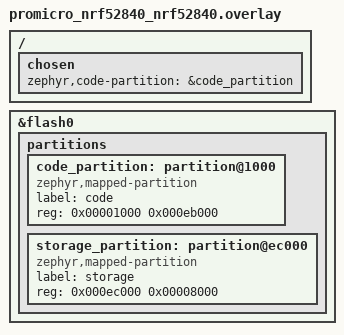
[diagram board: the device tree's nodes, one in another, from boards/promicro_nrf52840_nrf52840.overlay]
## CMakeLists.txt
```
#
# Copyright (c) 2025 Nordic Semiconductor ASA
#
# SPDX-License-Identifier: LicenseRef-Nordic-5-Clause
#

cmake_minimum_required(VERSION 3.20.0)

# The custom solomon,ssd1683 binding lives with the standalone app, one level up. Zephyr only
# looks for dts/bindings under the application directory, which is this one -- point it there
# too, or the e-paper node's width/height properties silently do not exist.
list(APPEND DTS_ROOT ${CMAKE_CURRENT_SOURCE_DIR}/..)

# The board's drivers, shared with the standalone firmware. Merged after prj.conf, so keep it free
# of anything an app would want to override -- see the file's header.
list(APPEND EXTRA_CONF_FILE ${CMAKE_CURRENT_SOURCE_DIR}/../conf/airink_hw.conf)

find_package(Zephyr HINTS $ENV{ZEPHYR_BASE})

project(matter-temperature-sensor)

# Enable GNU STD support.
include(${ZEPHYR_CONNECTEDHOMEIP_MODULE_DIR}/config/nrfconnect/app/enable-gnu-std.cmake)

# NORDIC SDK APP START

# Include all source files that are located in the Matter common directory.
include(${ZEPHYR_NRF_MODULE_DIR}/samples/matter/common/cmake/source_common.cmake)

# Include Data Model utils
include(${ZEPHYR_NRF_MODULE_DIR}/samples/matter/common/cmake/data_model.cmake)

include(${ZEPHYR_NRF_MODULE_DIR}/samples/matter/common/cmake/zap_helpers.cmake)
ncs_get_zap_parent_dir(ZAP_PARENT_DIR)

target_include_directories(app PRIVATE
  src
  ${ZAP_PARENT_DIR}
  # AirInk's own source tree, one level up.
  ${CMAKE_CURRENT_SOURCE_DIR}/../src
)

target_sources(app PRIVATE
  src/app_task.cpp
  src/main.cpp
)

# The AirInk device: the same sources the standalone firmware builds, minus its main() -- here
# app::run() is one thread among the CHIP event loop and OpenThread. Keep this list in step with
# the root CMakeLists.txt.
set(AIRINK_SRC ${CMAKE_CURRENT_SOURCE_DIR}/../src)
target_sources(app PRIVATE
  ${AIRINK_SRC}/app.cpp
  ${AIRINK_SRC}/menu.cpp
  ${AIRINK_SRC}/input/button.cpp
  ${AIRINK_SRC}/sensors/scd41.cpp
  ${AIRINK_SRC}/sensors/battery.cpp
  ${AIRINK_SRC}/ui/display_ui.cpp
  ${AIRINK_SRC}/ui/ui_platform.cpp
  # UI fonts (1bpp), generated via lv_font_conv: B612 for text, DSEG7 for values.
  ${AIRINK_SRC}/fonts/b612_48.c
  ${AIRINK_SRC}/fonts/b612_28.c
  ${AIRINK_SRC}/fonts/b612_16.c
  ${AIRINK_SRC}/fonts/b612_14.c
  ${AIRINK_SRC}/fonts/dseg7_48.c
  ${AIRINK_SRC}/fonts/dseg7_18.c
  # Vendored SSD16xx driver with a custom solomon,ssd1683 quirk (max 400x400, panel_gates=300)
  # for the GDEY042T81/SSD1683. Paired with CONFIG_SSD16XX=n.
  ${AIRINK_SRC}/drivers/ssd16xx.c
)

ncs_configure_data_model()
# NORDIC SDK APP END
```

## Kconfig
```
#
# Copyright (c) 2025 Nordic Semiconductor
#
# SPDX-License-Identifier: LicenseRef-Nordic-5-Clause
#
mainmenu "AirInk (Matter over Thread)"

choice OPENTHREAD_NORDIC_LIBRARY_CONFIGURATION
	default OPENTHREAD_NORDIC_LIBRARY_MTD
endchoice

choice OPENTHREAD_DEVICE_TYPE
	default OPENTHREAD_MTD
endchoice

config CHIP_ENABLE_ICD_SUPPORT
	default y

config CHIP_ICD_LIT_SUPPORT
	default y

config CHIP_ICD_SIT_SLOW_POLL_LIMIT
	default 5000

config CHIP_ICD_REPORT_ON_ACTIVE_MODE
	default y

# Reduce Thread TX output power to 0 dBm for SED device
config OPENTHREAD_DEFAULT_TX_POWER
	default 0

source "$(ZEPHYR_CONNECTEDHOMEIP_MODULE_DIR)/config/nrfconnect/chip-module/Kconfig.features"
source "$(ZEPHYR_CONNECTEDHOMEIP_MODULE_DIR)/config/nrfconnect/chip-module/Kconfig.defaults"
source "$(ZEPHYR_NRF_MODULE_DIR)/samples/matter/common/src/Kconfig"
source "Kconfig.zephyr"
```

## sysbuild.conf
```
#
# Copyright (c) 2025 Nordic Semiconductor
#
# SPDX-License-Identifier: LicenseRef-Nordic-5-Clause
#

SB_CONFIG_MATTER=y
SB_CONFIG_PARTITION_MANAGER=n

# No MCUboot: plain single image at 0x1000, flashed via the Adafruit UF2 bootloader
# (keeps AirInk's drag-drop field-update flow). Matter only imply's MCUboot, so this
# override is legal. Cost: no over-the-air OTA (would need external QSPI flash anyway).
SB_CONFIG_BOOTLOADER_NONE=y

# No factory data -- using the built-in example attestation provider (see prj.conf).
SB_CONFIG_MATTER_FACTORY_DATA_GENERATE=n

# No over-the-air OTA (no MCUboot). This is what injects CONFIG_CHIP_OTA_REQUESTOR into
# the app image; off here drops the DFU image manager (IMG_MANAGER/DFU_TARGET/
# STREAM_FLASH) that needs slot0/slot1 partitions we don't have. Field updates are UF2.
SB_CONFIG_MATTER_OTA=n
```

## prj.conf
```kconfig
#
# Copyright (c) 2025 Nordic Semiconductor ASA
#
# SPDX-License-Identifier: LicenseRef-Nordic-5-Clause
#

# Enable CHIP
CONFIG_CHIP=y
CONFIG_CHIP_PROJECT_CONFIG="src/chip_project_config.h"

# Configure ZAP file name
CONFIG_NCS_SAMPLE_MATTER_ZAP_FILE_PATH="${APPLICATION_CONFIG_DIR}/src/default_zap/airink.zap"

# Device identity -- what a controller shows in its UI (Basic Information cluster). Left
# unset, every one of these falls back to a sample/test default: product name
# "Matter Temperature Sensor", hardware version "prerelease", serial "11223344556677889900".
# The serial is the same on every board we flash; per-device serials would need factory
# data, which we deliberately dropped (see CHIP_FACTORY_DATA_NONE below).
CONFIG_CHIP_DEVICE_VENDOR_NAME="AirInk"
CONFIG_CHIP_DEVICE_PRODUCT_NAME="AirInk CO2 Monitor"
CONFIG_CHIP_DEVICE_HARDWARE_VERSION=1
CONFIG_CHIP_DEVICE_HARDWARE_VERSION_STRING="rev A"
CONFIG_CHIP_DEVICE_SERIAL_NUMBER="AIRINK-0001"
# The software version comes from the VERSION file (the Kconfig is hidden once APPVERSION
# is set), not from here.

# Based on https://github.com/project-chip/connectedhomeip/blob/482e6fd03196a6de45465a90003947ef4b86e0b1/docs/examples/discussion/PID_allocation_for_example_apps.md)
# 0x8000 (32768), to match the example provider's DAC (FFF1-8000). Was 32781 (0x800D).
CONFIG_CHIP_DEVICE_PRODUCT_ID=32768
CONFIG_STD_CPP17=y

# Enable Matter pairing automatically on application start.
CONFIG_CHIP_ENABLE_PAIRING_AUTOSTART=y

# Enable Matter extended announcement and increase duration to 1 hour.
CONFIG_CHIP_BLE_EXT_ADVERTISING=y
CONFIG_CHIP_BLE_ADVERTISING_DURATION=60

# The DK library drives the buttons and LEDs of a Nordic development kit. We have neither: one
# button, no status LEDs, and that button already belongs to Zephyr's gpio-keys + input-longpress
# drivers (src/input/button.cpp). Two owners on one pin is not a style question -- the DK library
# takes raw GPIO callbacks and *disables the pin interrupt* while it debounces, which is the same
# interrupt gpio-keys is using. Off. Nrf::Board and the LED widgets are wholly #ifdef'd on this,
# so they degrade to no-ops (and the sample's "LED index out of the range" boot error goes away).
CONFIG_DK_LIBRARY=n

# Bluetooth Low Energy configuration. This name is the only one actually on the air during
# BLE commissioning -- the Matter commissionable payload carries no device name (see
# CHIP_DEVICE_CONFIG_ENABLE_COMMISSIONABLE_DEVICE_NAME in chip_project_config.h), which is
# why a controller shows a generic "Matter Accessory" until it can read Basic Information.
CONFIG_BT_DEVICE_NAME="AirInk"
CONFIG_BT_DEVICE_NAME_MAX=18

# Suspend devices when the CPU goes into sleep
CONFIG_PM_DEVICE=y

# Other settings
CONFIG_THREAD_NAME=y
CONFIG_MPU_STACK_GUARD=y
CONFIG_RESET_ON_FATAL_ERROR=n
# Shell off for the bring-up (saves flash; RAM barely).
CONFIG_CHIP_LIB_SHELL=n

# Reduce application size
CONFIG_USE_SEGGER_RTT=n

# Built-in example attestation provider: it ships a complete, self-consistent set --
# DAC (FFF1/8000), PAI (FFF1), and a CD (kCdForAllExamples, covering PID 0x8000..) -- all
# hardcoded, no factory-data partition, no chip-cert host tool needed. The device's PID
# must be 0x8000 to match the example DAC (set below); the CD covers it. With HA's
# enable_test_net_dcl=true the test certs are trusted. Passcode stays custom (below).
CONFIG_CHIP_FACTORY_DATA_NONE=y
CONFIG_CHIP_DEVICE_SPAKE2_PASSCODE=528722
# The SPAKE2+ verifier is a STATIC Kconfig default -- it is NOT recomputed when the
# passcode changes. Its default belongs to passcode 20202021, so a custom passcode with
# the stock verifier makes the device advertise 528722 while proving knowledge of
# 20202021: the commissioner's Pake2 check fails and it drops BLE mid-PASE.
# Generated for passcode 528722 / this salt / 1000 iterations with
#   scripts/tools/spake2p/spake2p.py gen-verifier -p 528722 -s <salt> -i 1000
CONFIG_CHIP_DEVICE_SPAKE2_TEST_VERIFIER="LdCcPszn0rvDj59TPG1d2kQstzG8hR1Ty0PvpWUYgeUEPahM+o4wma7TlCWuMm8Z4blyJEp/VQdDBcCTW8c3JbFoMFvieDwXAbMtL/i3GSFf/d42EjivkDMMpDw2K9Fohg=="

# (OTA requestor is turned off at the sysbuild layer: SB_CONFIG_MATTER_OTA=n. It's
# injected via .config.sysbuild, which is merged AFTER prj.conf, so a prj.conf override
# here would be ignored -- the switch has to live in sysbuild.conf.)

# Matter has its own bootloader choice, separate from the sysbuild one, defaulting to
# CHIP_BOOTLOADER_MCUBOOT which hard-selects IMG_MANAGER (whose STREAM_FLASH dependency
# is now off). Pick NONE -- we have no MCUboot.
CONFIG_CHIP_BOOTLOADER_NONE=y

# NFC onboarding pulls in the NFC T2T nrfxlib, but the promicro board doesn't enable the
# nrfx NFCT driver (the DK does) -> undefined nrfx_nfct_* at link. We commission over BLE
# with the QR / manual code, so drop NFC onboarding.
CONFIG_CHIP_NFC_ONBOARDING_PAYLOAD=n

# The board's drivers -- SCD41, battery ADC, e-paper, LVGL, the button, the uart0 console, the
# UF2 output -- are not repeated here. They live in conf/airink_hw.conf, shared with the standalone
# firmware and pulled in by CMakeLists.txt. Below is only what this build decides differently.
#
# The one exception is the LVGL pool: it is a tuning knob, not a board fact, and this build cannot
# afford the standalone one's 48 KB.
# All views are built once and kept resident, and glyph draw buffers (b612_48 is ~2 KB) come out of
# the pool during a render. Running it dry is an MPU fault in lv_draw_label, not a graceful failure.
# Trimmed to the measured peak plus headroom -- ui::log_pool() reports "peak 17644 of 24576 B" at
# boot, with every view resident. If you raise the UI's appetite, read that line; do not guess.
CONFIG_LV_Z_MEM_POOL_SIZE=24576

# --- Stacks. RAM is what this build is short of; every kilobyte here is one the UI cannot have.
# main() no longer renders anything -- it only runs the CHIP task queue (AppTask::StartApp), and
# the 400x300 render with its 48 px glyph rasterisation moved to AirInk's own thread, which is
# sized for it in app_task.cpp. The sample's 6 KB was for a main that did the work.
CONFIG_MAIN_STACK_SIZE=3072
# The CHIP event loop. Our cluster writes take the stack lock from AirInk's thread rather than
# running here, so this carries Matter's own work only.
CONFIG_CHIP_TASK_STACK_SIZE=6144

# CHIP heap. The 10 KB default cannot build the NetworkCommissioning ScanNetworks
# response (cluster 0x0031 cmd 0x0000): the device returns NO_MEMORY ("Adding response
# failed: b"), the commissioner stalls, the fail-safe expires and the fabric is rolled
# back. Home Assistant issues ScanNetworks during commissioning (the phone framework does
# not, which is why that path used to get through). It looks like an obvious 8 KB to reclaim now
# that RAM is tight -- it is not.
CONFIG_CHIP_MALLOC_SYS_HEAP_SIZE=40960
```

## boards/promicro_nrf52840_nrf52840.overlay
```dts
/*
 * The Matter build's devicetree: AirInk's hardware (the shared .dtsi -- same SCD41, button,
 * e-paper, battery divider and uart0 console as the standalone firmware) plus the one thing
 * that differs, a partition map.
 *
 * No MCUboot, no external flash. Plain single image linked at 0x1000 -- exactly where the
 * Adafruit UF2 bootloader (top of flash) expects a SoftDevice-less app, the same layout the
 * standalone firmware ships with. Storage (Matter NVS) sits just below the reserved bootloader
 * region so the app never touches it.
 *
 * Flash map (1 MB):
 *   0x00000000  MBR (part of the Adafruit bootloader, already present)
 *   0x00001000  code       -> 0xEB000 = 940 KB
 *   0x000EC000  storage    -> 0x08000 = 32 KB    (Matter fabric NVS)
 *   0x000F4000  Adafruit bootloader + settings (48 KB) -- RESERVED, no partition
 */

#include "../../dts/airink_hw.dtsi"

/delete-node/ &boot_partition;
/delete-node/ &slot0_partition;
/delete-node/ &slot1_partition;
/delete-node/ &storage_partition;

/ {
	chosen {
		zephyr,code-partition = &code_partition;
	};
};

&flash0 {
	partitions {
		code_partition: partition@1000 {
			compatible = "zephyr,mapped-partition";
			label = "code";
			reg = <0x00001000 0x000eb000>;
		};

		storage_partition: partition@ec000 {
			compatible = "zephyr,mapped-partition";
			label = "storage";
			reg = <0x000ec000 0x00008000>;
		};
	};
};
```

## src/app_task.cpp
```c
/*
 * Copyright (c) 2025 Nordic Semiconductor ASA
 *
 * SPDX-License-Identifier: LicenseRef-Nordic-5-Clause
 */

#include "app_task.h"

#include "app/matter_init.h"
#include "app/matter_event_handler.h"
#include "app/task_executor.h"
#include "board/board.h"
#include "clusters/identify.h"
#include "lib/core/CHIPError.h"

#include "app.hpp"

#include <app-common/zap-generated/attributes/Accessors.h>
#include <app/clusters/air-quality-server/air-quality-server.h>
#include <app/clusters/concentration-measurement-server/concentration-measurement-server.h>
#include <app/clusters/power-source-server/power-source-server.h>

#include <zephyr/kernel.h>
#include <zephyr/logging/log.h>

LOG_MODULE_DECLARE(app, CONFIG_CHIP_APP_LOG_LEVEL);

using namespace ::chip;
using namespace ::chip::app; /* NB: this makes a bare `app::` ambiguous with AirInk's own
					  namespace -- reach for the latter as ::app:: */
using namespace ::chip::DeviceLayer;
using namespace ::chip::app::Clusters;

namespace
{
/* Endpoint map -- see src/default_zap/airink.zap. One physical sensor, one endpoint: the Air
 * Quality Sensor device type may carry temperature and humidity alongside the CO2 clusters, so
 * everything the SCD41 measures lives on endpoint 1. (Splitting it into a temperature, humidity
 * and air quality endpoint also works, but each device type mandates its own Identify cluster,
 * and a controller then shows three "Identify" entities for one device.) */
constexpr EndpointId kPowerSourceEndpointId = 0; /* root node */
constexpr EndpointId kSensorEndpointId = 1;

/* The battery powers the whole node. */
EndpointId sPoweredEndpoints[] = { 0, 1 };

Nrf::Matter::IdentifyCluster sIdentifyCluster(kSensorEndpointId);

/* Unlike temperature and humidity, the air quality and concentration clusters are not backed
 * by the ember attribute store -- they are served by these AttributeAccessInterface instances,
 * which is why the ZAP marks their attributes "External". The concentration template flags are
 * <Numeric, Level, MediumLevel, CriticalLevel, Peak, Average>: we report a numeric ppm value
 * and nothing else, and the ZAP's attribute list must match that exactly. */
AirQuality::Instance sAirQuality(kSensorEndpointId,
				 BitMask<AirQuality::Feature, uint32_t>(AirQuality::Feature::kModerate,
									AirQuality::Feature::kFair,
									AirQuality::Feature::kVeryPoor,
									AirQuality::Feature::kExtremelyPoor));

ConcentrationMeasurement::Instance<true, false, false, false, false, false>
	sCo2(kSensorEndpointId, CarbonDioxideConcentrationMeasurement::Id,
	     ConcentrationMeasurement::MeasurementMediumEnum::kAir,
	     ConcentrationMeasurement::MeasurementUnitEnum::kPpm);

/* SCD41 datasheet operating range. */
constexpr float kCo2MinPpm = 400.0f;
constexpr float kCo2MaxPpm = 5000.0f;

/* AirInk's own thread. It renders a 400x300 mono frame with 48 px fonts and blocks ~5 s in a
 * CO2 single-shot, so it gets the big stack -- and it gets it here rather than on the CHIP event
 * loop, which OpenThread needs responsive. Priority below the cooperative CHIP/OT threads. */
K_THREAD_STACK_DEFINE(sAirInkStack, 8192);
k_thread sAirInkThread;

/* CO2 as a proxy for air quality. The thresholds are the usual indoor-air guidance (Pettenkofer's
 * 1000 ppm is the "still fine" line; 2000 ppm is where concentration measurably suffers). */
AirQuality::AirQualityEnum AirQualityFromCo2(uint16_t ppm)
{
	if (ppm < 800) {
		return AirQuality::AirQualityEnum::kGood;
	}
	if (ppm < 1000) {
		return AirQuality::AirQualityEnum::kFair;
	}
	if (ppm < 1400) {
		return AirQuality::AirQualityEnum::kModerate;
	}
	if (ppm < 2000) {
		return AirQuality::AirQualityEnum::kPoor;
	}
	if (ppm < 5000) {
		return AirQuality::AirQualityEnum::kVeryPoor;
	}
	return AirQuality::AirQualityEnum::kExtremelyPoor;
}

/* Both hooks run on AirInk's thread, so they take the CHIP stack lock -- the documented way to
 * touch cluster attributes from outside the event loop. Holding it across four setters keeps the
 * reading self-consistent for anyone reading it at that moment; none of them block. */
void PublishReading(const Scd41Reading &r)
{
	PlatformMgr().LockChipStack();
	TemperatureMeasurement::Attributes::MeasuredValue::Set(kSensorEndpointId,
							       static_cast<int16_t>(r.temp_x100));
	RelativeHumidityMeasurement::Attributes::MeasuredValue::Set(kSensorEndpointId, r.hum_x100);
	sCo2.SetMeasuredValue(DataModel::Nullable<float>(static_cast<float>(r.co2_ppm)));
	sAirQuality.UpdateAirQuality(AirQualityFromCo2(r.co2_ppm));
	PlatformMgr().UnlockChipStack();
}

void PublishBattery(const battery::State &bat)
{
	PlatformMgr().LockChipStack();
	/* Matter counts the battery in half percent. */
	PowerSource::Attributes::BatPercentRemaining::Set(kPowerSourceEndpointId,
							  static_cast<uint8_t>(bat.pct * 2));
	PowerSource::Attributes::BatChargeState::Set(kPowerSourceEndpointId,
						     bat.charging ? PowerSource::BatChargeStateEnum::kIsCharging
								  : PowerSource::BatChargeStateEnum::kIsNotCharging);
	PowerSource::Attributes::BatChargeLevel::Set(kPowerSourceEndpointId,
						     bat.low ? PowerSource::BatChargeLevelEnum::kCritical
							     : PowerSource::BatChargeLevelEnum::kOk);
	PlatformMgr().UnlockChipStack();
}

/* Runs on the CHIP thread. Only records the radio state; the status bar belongs to AirInk's
 * thread, which picks the value up on its next cycle. */
void MatterEventHandler(const ChipDeviceEvent *event, intptr_t)
{
	switch (event->Type) {
	case DeviceEventType::kCHIPoBLEAdvertisingChange:
		::app::set_link(event->CHIPoBLEAdvertisingChange.Result == kActivity_Started
				      ? ui::Link::BleAdv
				      : ui::Link::None);
		break;
	case DeviceEventType::kThreadConnectivityChange:
		::app::set_link(event->ThreadConnectivityChange.Result == kConnectivity_Established
				      ? ui::Link::ThreadConnected
				      : ui::Link::ThreadJoining);
		break;
	default:
		break;
	}
}

void AirInkThread(void *, void *, void *)
{
	const ::app::Hooks hooks = { .reading = PublishReading, .battery = PublishBattery };
	::app::set_hooks(hooks);
	::app::run(); /* never returns */
}

} /* namespace */

CHIP_ERROR AppTask::Init()
{
	ReturnErrorOnFailure(Nrf::Matter::PrepareServer());
	ReturnErrorOnFailure(Nrf::Matter::RegisterEventHandler(MatterEventHandler, 0));
	ReturnErrorOnFailure(sIdentifyCluster.Init());
	ReturnErrorOnFailure(Nrf::Matter::StartServer());

	/* Only now. These three reach into the ember endpoint tables, which do not exist until
	 * Server::Init() has run emberAfEndpointConfigure() -- i.e. until StartServer() returns.
	 * AirQuality::Instance::Init() asserts on it with VerifyOrDie (a boot-time abort), the
	 * concentration instance merely returns an error and would then silently never publish.
	 * The event loop is live by now, so take the stack lock. */
	CHIP_ERROR err = CHIP_NO_ERROR;
	PlatformMgr().LockChipStack();
	err = sAirQuality.Init();
	if (err == CHIP_NO_ERROR) {
		err = sCo2.Init();
	}
	if (err == CHIP_NO_ERROR) {
		/* Static facts about the source: the SCD41's range, and the endpoints it powers. */
		sCo2.SetMinMeasuredValue(DataModel::Nullable<float>(kCo2MinPpm));
		sCo2.SetMaxMeasuredValue(DataModel::Nullable<float>(kCo2MaxPpm));
		PowerSourceServer::Instance().SetEndpointList(kPowerSourceEndpointId,
							      Span<EndpointId>(sPoweredEndpoints));
	}
	PlatformMgr().UnlockChipStack();

	return err;
}

CHIP_ERROR AppTask::StartApp()
{
	ReturnErrorOnFailure(Init());

	k_thread_create(&sAirInkThread, sAirInkStack, K_THREAD_STACK_SIZEOF(sAirInkStack), AirInkThread,
			nullptr, nullptr, nullptr, K_PRIO_PREEMPT(10), 0, K_NO_WAIT);
	k_thread_name_set(&sAirInkThread, "airink");

	while (true) {
		Nrf::DispatchNextTask();
	}

	return CHIP_NO_ERROR;
}
```

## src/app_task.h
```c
/*
 * Copyright (c) 2025 Nordic Semiconductor ASA
 *
 * SPDX-License-Identifier: LicenseRef-Nordic-5-Clause
 */

#pragma once

#include <platform/CHIPDeviceLayer.h>

/** Brings up Matter, then hands the device itself to AirInk.
 *
 * StartApp() runs the CHIP task queue on the main thread forever. Everything AirInk does --
 * the panel, the SCD41, the button, the menu -- runs on a thread of its own (app::run(), see
 * src/app.hpp), because a full CO2 read blocks for ~5 s and an e-paper refresh for ~2 s, and
 * neither may sit on the CHIP event loop while OpenThread waits to poll its parent.
 *
 * Direction of travel: AirInk measures, and hands each reading to Matter. Matter never reaches
 * back into the UI -- the network state is left where the loop picks it up (app::set_link()).
 */
class AppTask {
public:
	static AppTask &Instance()
	{
		static AppTask sAppTask;
		return sAppTask;
	};

	CHIP_ERROR StartApp();

private:
	CHIP_ERROR Init();
};
```

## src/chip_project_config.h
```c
/*
 * Copyright (c) 2025 Nordic Semiconductor ASA
 *
 * SPDX-License-Identifier: LicenseRef-Nordic-5-Clause
 */

/**
 *    @file
 *          Example project configuration file for CHIP.
 *
 *          This is a place to put application or project-specific overrides
 *          to the default configuration values for general CHIP features.
 *
 */

#pragma once

/**
 * Include a device name in the commissionable-node advertisement. Off by default, which is
 * why a commissioner has nothing to call the device before it can read Basic Information
 * and shows a generic placeholder ("Matter Accessory" in Home Assistant). Note this only
 * populates the DNS-SD commissionable record; over BLE the name a scanner sees is
 * CONFIG_BT_DEVICE_NAME. Whether a given controller surfaces either is up to the controller.
 */
#define CHIP_DEVICE_CONFIG_ENABLE_COMMISSIONABLE_DEVICE_NAME 1
#define CHIP_DEVICE_CONFIG_DEVICE_NAME "AirInk"
```
